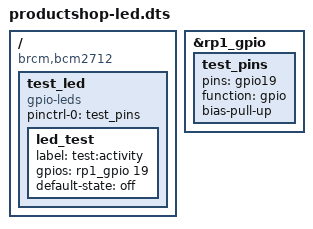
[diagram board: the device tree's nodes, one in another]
/dts-v1/;
/plugin/;

/{
    compatible = "brcm,bcm2712";

    // Test just GPIO pins first
    fragment@0 {
        target = <&rp1_gpio>;
        __overlay__ {
            test_pins: test_pins {
                pins = "gpio19";  /* NFC LED */
                function = "gpio";
                bias-pull-up;
            };
        };
    };

    // Test simple LED
    fragment@1 {
        target-path = "/";
        __overlay__ {
            test_led {
                compatible = "gpio-leds";
                pinctrl-names = "default";
                pinctrl-0 = <&test_pins>;
                
                led_test {
                    label = "test:activity";
                    gpios = <&rp1_gpio 19 0>;
                    default-state = "off";
                };
            };
        };
    };
};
